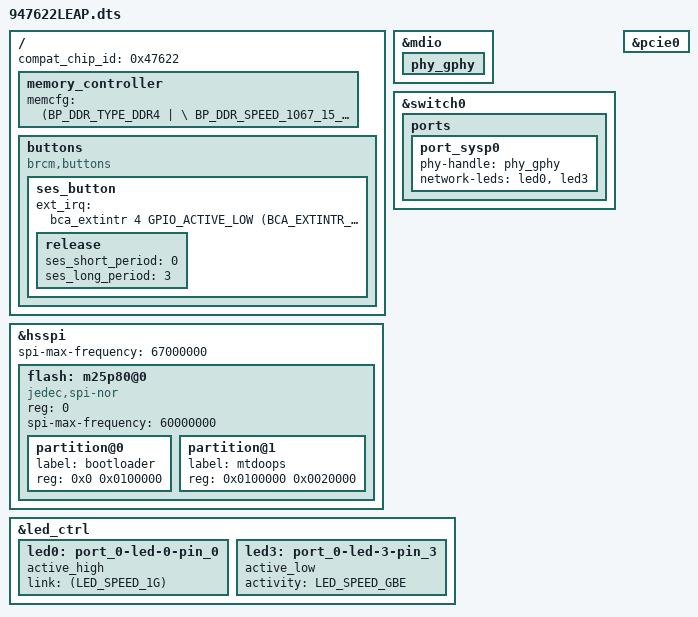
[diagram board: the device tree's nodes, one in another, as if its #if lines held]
#include "47622.dtsi"

/ {
	compat_chip_id = <0x47622>;
    memory_controller {
        memcfg = <(BP_DDR_TYPE_DDR4           | \
                   BP_DDR_SPEED_1067_15_15_15 | \
                   BP_DDR_TOTAL_SIZE_2048MB   | \
                   BP_DDR_DEVICE_WIDTH_8      | \
                   BP_DDR_TOTAL_WIDTH_16BIT   | \
                   BP_DDR_SSC_CONFIG_1)>;
    };

	buttons {
		compatible = "brcm,buttons";
		ses_button {
			ext_irq = <&bca_extintr 4 GPIO_ACTIVE_LOW (BCA_EXTINTR_TYPE_LOW_LEVEL | BCA_EXTINTR_TYPE_SENSE_EDGE)>;
			release {
				ses_short_period = <0>;
				ses_long_period = <3>;
			};
		};
	};
};

&hsspi {
	spi-max-frequency = <67000000>;
	status = "okay";
	flash: m25p80@0 {
		status = "okay";
		compatible = "jedec,spi-nor";
		reg = <0>; /* chip select 0 */
		spi-max-frequency = <60000000>;
		#address-cells = <1>;
		#size-cells = <1>;
		partition@0 {
			label = "bootloader";
			reg = <0x0 0x0100000>;
		};
		partition@1 {
			label = "mtdoops";
			reg = <0x0100000 0x0020000>;
		};
	 };
};

&mdio {
    /* Port PHY mapping:
            port_sysp0 <---> phy_gphy
     */
	phy_gphy {
		status = "okay";
	};
};

&switch0 {
	ports {
		port_sysp0 {
			phy-handle = <&phy_gphy>;
			network-leds = <&led0 &led3>;
			status = "okay";
		};
	};
};

&led_ctrl {
	led0: port_0-led-0-pin_0 {
		active_high;
		link = <(LED_SPEED_1G)>;
		status = "okay";
	};
	led3: port_0-led-3-pin_3 {
		active_low;
		activity = <LED_SPEED_GBE>;
		status = "okay";
	};
};

#if defined(CONFIG_BCM_PCIE_HCD) || defined (CONFIG_BCM_PCIE_HCD_MODULE)
&pcie0 {
	status = "okay";
};
#endif

